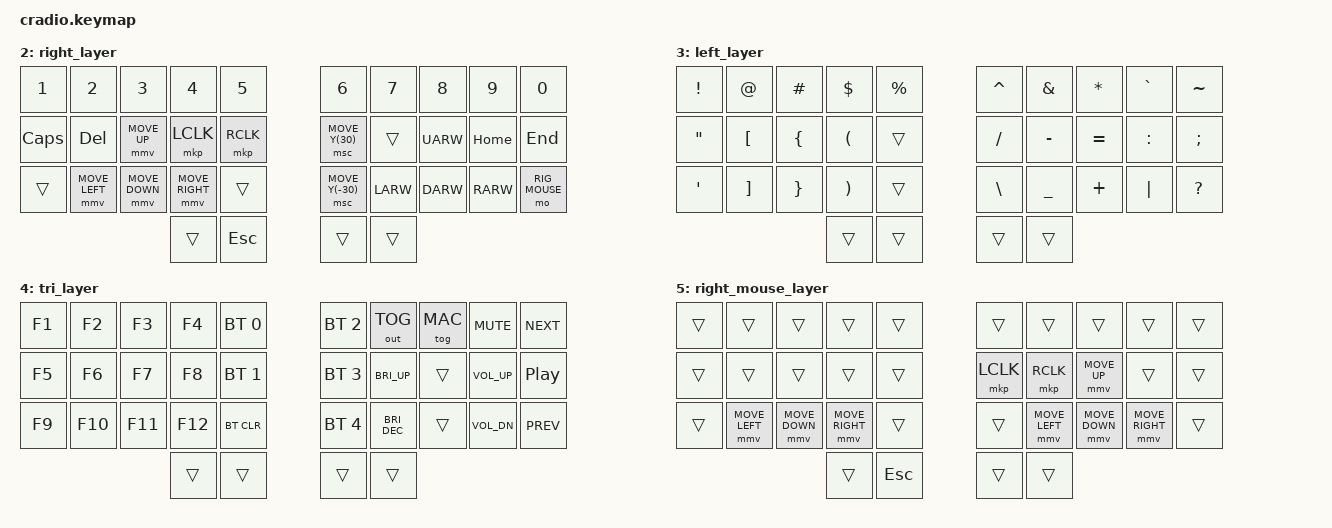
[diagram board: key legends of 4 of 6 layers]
#include <behaviors.dtsi>
#include <dt-bindings/zmk/keys.h>
#include <dt-bindings/zmk/bt.h>
#include <dt-bindings/zmk/outputs.h>

//#define ZMK_MOUSE_DEFAULT_SCRL_VAL 1

#include <dt-bindings/zmk/mouse.h>

// Home row mods macro
#define MHRML(k2,k3,k4) &mt LALT k2  &mt LCTRL k3  &mt LGUI k4
#define MHRMR(k1,k2,k3) &mt RGUI k1  &mt RCTRL k2  &mt RALT k3
#define WHRML(k2,k3,k4) &mt LALT k2  &mt LGUI k3  &mt LCTRL k4
#define WHRMR(k1,k2,k3) &mt RCTRL k1  &mt RGUI k2  &mt RALT k3

#define WIN 0
#define MAC 1
#define RIG 2
#define LEF 3
#define TRI 4
#define RIG_MOUSE 5

&mmv {
    time-to-max-speed-ms = <500>;
};

/ {
    behaviors {
        //ht: hold_tap {
        //    label = "hold_tap";
        //    compatible = "zmk,behavior-hold-tap";
        //    #binding-cells = <2>;
        //    flavor = "tap-preferred";
        //    tapping-term-ms = <220>;
        //    quick-tap-ms = <150>;
       //     global-quick-tap;
       //     bindings = <&kp>, <&kp>;
       // };
       // hms: hold_tap {
       //     label = "hold_tap_mouse_scroll";
       //     compatible = "zmk,behavior-hold-tap";
       //     #binding-cells = <2>;
       //     flavor = "tap-preferred";
       //     tapping-term-ms = <220>;
       //     quick-tap-ms = <150>;
       //     global-quick-tap;
        //    bindings = <&kp>, <&msc>;
        //};
    };

    conditional_layers {
        compatible = "zmk,conditional-layers";
        tri_layer {
            if-layers = <RIG LEF>;
            then-layer = <TRI>;
        };
    };

    keymap {
        compatible = "zmk,keymap";
        windows_layer {
            bindings = <
        //╭──────────┬──────────┬──────────┬──────────┬──────────╮   ╭──────────┬──────────┬──────────┬──────────┬──────────╮
        //│  Q       │  W       │  E       │  R       │  T       │   │  Y       │  U       │  I       │  O       │  P       │
            &kp Q      &kp W      &kp E      &kp R      &kp T          &kp Y      &kp U      &kp I      &kp O      &kp P
        //├──────────┼──────────┼──────────┼──────────┼──────────┤   ├──────────┼──────────┼──────────┼──────────┼──────────┤
        //│  A       │  S       │  D       │  F       │  G       │   │  H       │  J       │  K       │  L       │BACKSPACE │
            &kp A    WHRML(S,         D,         F)     &kp G          &kp H      WHRMR(J,        K,         L)   &kp BSPC
        //├──────────┼──────────┼──────────┼──────────┼──────────┤   ├──────────┼──────────┼──────────┼──────────┼──────────┤
        //│  Z       │  X       │  C       │  V       │  B       │   │  N       │  M       │ , <      │ . >      │ ENTER    │
            &kp Z      &kp X      &kp C      &kp V      &kp B          &kp N      &kp M      &kp COMMA  &kp DOT    &kp ENTER
        //╰──────────┴──────────┴──────────┼──────────┼──────────┤   ├──────────┼──────────┼──────────┴──────────┴──────────╯
                                           &lt LEF TAB  &kp LSHIFT    &kp SPACE  &lt RIG TAB
        //                                 ╰──────────┴──────────╯   ╰──────────┴──────────╯
            >;
        };

        mac_layer {
            bindings = <
        //╭──────────┬──────────┬──────────┬──────────┬──────────╮   ╭──────────┬──────────┬──────────┬──────────┬──────────╮
        //│  Q       │  W       │  E       │  R       │  T       │   │  Y       │  U       │  I       │  O       │  P       │
            &kp Q      &kp W      &kp E      &kp R      &kp T          &kp Y      &kp U      &kp I      &kp O      &kp P
        //├──────────┼──────────┼──────────┼──────────┼──────────┤   ├──────────┼──────────┼──────────┼──────────┼──────────┤
        //│  A       │  S       │  D       │  F       │  G       │   │  H       │  J       │  K       │  L       │BACKSPACE │
            &kp A     MHRML(S,         D,         F)     &kp G          &kp H      MHRMR(J,        K,           L)   &kp BSPC
        //├──────────┼──────────┼──────────┼──────────┼──────────┤   ├──────────┼──────────┼──────────┼──────────┼──────────┤
        //│  Z       │  X       │  C       │  V       │  B       │   │  N       │  M       │ , <      │ . >      │ ENTER    │
            &kp Z      &kp X      &kp C      &kp V      &kp B          &kp N      &kp M      &kp COMMA  &kp DOT    &kp ENTER
        //╰──────────┴──────────┴──────────┼──────────┼──────────┤   ├──────────┼──────────┼──────────┴──────────┴──────────╯
                                           &lt LEF TAB  &kp LSHIFT    &kp SPACE  &lt RIG TAB
        //                                 ╰──────────┴──────────╯   ╰──────────┴──────────╯
            >;
        };

        right_layer {
            bindings = <
        //╭──────────┬──────────┬──────────┬──────────┬──────────╮   ╭──────────┬──────────┬──────────┬──────────┬──────────╮
        //│ 1        │  2       │  3       │  4       │  5       │   │ 6        │ 7        │ 8        │ 9        │   0      │
            &kp N1    &kp N2       &kp N3    &kp N4     &kp N5          &kp N6     &kp N7     &kp N8     &kp N9      &kp N0
        //├──────────┼──────────┼──────────┼──────────┼──────────┤   ├──────────┼──────────┼──────────┼──────────┼──────────┤
        //│CAPSLOCK  │          │MouseUp   │LMCLick   │ RMClick  |   |          │          │ UP       │   HOME   │   END    │
            &kp CAPS   &kp DEL   &mmv MOVE_UP &mkp LCLK  &mkp RCLK     &msc MOVE_Y(30) &trans   &kp UARW   &kp HOME   &kp END
        //├──────────┼──────────┼──────────┼──────────┼──────────┤   ├──────────┼──────────┼──────────┼──────────┼──────────┤
        //│          │          │          │          │          │   │          │   LEFT   │  DOWN    │  RIGHT   │          │
        &trans &mmv MOVE_LEFT &mmv MOVE_DOWN &mmv MOVE_RIGHT &trans &msc MOVE_Y(-30)  &kp LARW  &kp DARW  &kp RARW  &mo RIG_MOUSE
        //╰──────────┴──────────┴──────────┼──────────┼──────────┤   ├──────────┼──────────┼──────────┴──────────┴──────────╯
                                             &trans     &kp ESC        &trans     &trans
        //                                 ╰──────────┴──────────╯   ╰──────────┴──────────╯
            >;
        };

        left_layer {
            bindings = <
        //╭──────────┬──────────┬──────────┬──────────┬──────────╮   ╭──────────┬──────────┬──────────┬──────────┬──────────╮
        //│  !       │  @       │  #       │  $       │  %       │   │  ^       │  &       │  *       │  `       │  ~       │
            &kp EXCL   &kp AT     &kp HASH   &kp DLLR   &kp PRCNT      &kp CARET  &kp AMPS   &kp ASTRK  &kp GRAVE   &kp TILDE
        //├──────────┼──────────┼──────────┼──────────┼──────────┤   ├──────────┼──────────┼──────────┼──────────┼──────────┤
        //│  "       │  [       │  {       │  (       │          │   │   /      │  -       │  =       │     :    │  ;       │
            &kp DQT  &kp LBKT   &kp LBRC   &kp LPAR   &trans         &kp FSLH   &kp MINUS  &kp EQUAL  &kp COLON   &kp SEMI
        //├──────────┼──────────┼──────────┼──────────┼──────────┤   ├──────────┼──────────┼──────────┼──────────┼──────────┤
        //│  '       │  ]       │  }       │  )       │          │   │    \     │  _       │  +       │  │       │   ?      │
            &kp SQT     &kp RBKT   &kp RBRC   &kp RPAR   &trans         &kp BSLH   &kp UNDER  &kp PLUS   &kp PIPE  &kp QMARK
        //╰──────────┴──────────┴──────────┼──────────┼──────────┤   ├──────────┼──────────┼──────────┴──────────┴──────────╯
                                             &trans     &trans         &trans     &trans
        //                                 ╰──────────┴──────────╯   ╰──────────┴──────────╯
            >;
        };

        tri_layer {
            bindings = <
        //╭──────────┬──────────┬──────────┬───────────┬────────────╮   ╭────────────┬────────────┬──────────┬───────────┬──────────╮
        //│  F1      │  F2      │  F3      │  F4       │ PROFILE 0  │   │ PROFILE 2  │ TOGGLEOUT  │ MACOS  │ VOL MUTE  │ NEXTSONG │
            &kp F1     &kp F2     &kp F3     &kp F4     &bt BT_SEL 0     &bt BT_SEL 2  &out OUT_TOG &tog MAC  &kp C_MUTE  &kp C_NEXT
        //├──────────┼──────────┼──────────┼───────────┼────────────┤   ├────────────┼────────────┼──────────┼───────────┼──────────┤
        //│  F5      │  F6      │  F7      │  F8       │ PROFILE 1  │   │ PROFILE 3  │ INC BRIGHT │          │  VOL UP   │PAUSEMUSIC│
            &kp F5     &kp F6     &kp F7     &kp F8     &bt BT_SEL 1     &bt BT_SEL 3  &kp C_BRI_UP  &trans   &kp C_VOL_UP  &kp C_PP
        //├──────────┼──────────┼──────────┼───────────┼────────────┤   ├────────────┼────────────┼──────────┼───────────┼──────────┤
        //│  F9      │  F10     │  F11     │  F12      │  CLEAR BT  │   │ PROFILE 4  │ DEC BRIGHT │          |  VOL DOWN │ PREVSONG │
            &kp F9     &kp F10    &kp F11    &kp F12     &bt BT_CLR      &bt BT_SEL 4  &kp C_BRI_DEC  &trans   &kp C_VOL_DN &kp C_PREV
        //╰──────────┴──────────┴──────────┼───────────┼────────────┤   ├────────────┼────────────┼──────────┴───────────┴──────────╯
                                                &trans     &trans         &trans     &trans
        //                                  ╰───────────┴──────────╯   ╰──────────┴────────────╯
            >;
        };

        right_mouse_layer {
            bindings = <
        //╭──────────┬──────────┬──────────┬──────────┬──────────╮   ╭──────────┬──────────┬──────────┬──────────┬──────────╮
        //│          │          │          │          │          │   │          │          │          │          │          │
            &trans    &trans      &trans     &trans     &trans        &trans      &trans      &trans     &trans     &trans
        //├──────────┼──────────┼──────────┼──────────┼──────────┤   ├──────────┼──────────┼──────────┼──────────┼──────────┤
        //│          │          │          │          │          |   |          │          │          │          │          │
            &trans    &trans      &trans      &trans     &trans       &mkp LCLK   &mkp RCLK &mmv MOVE_UP  &trans  &trans
        //├──────────┼──────────┼──────────┼──────────┼──────────┤   ├──────────┼──────────┼──────────┼──────────┼──────────┤
        //│          │          │          │          │          │   │          │          │          │          │          │
        &trans &mmv MOVE_LEFT &mmv MOVE_DOWN &mmv MOVE_RIGHT &trans &trans &mmv MOVE_LEFT &mmv MOVE_DOWN  &mmv MOVE_RIGHT  &trans
        //╰──────────┴──────────┴──────────┼──────────┼──────────┤   ├──────────┼──────────┼──────────┴──────────┴──────────╯
                                             &trans     &kp ESC        &trans     &trans
        //                                 ╰──────────┴──────────╯   ╰──────────┴──────────╯
            >;
        };
    };
};
